# MCAN register map
Vendor: Texas Instruments
Registers are 32-bit, access per field, reset 0x0 unless marked. A register's access mark holds for its fields unless they carry their own. Offsets are as the file gives them; [hi:lo] are bit positions; {n}, {i} and the like mark numbered series; 'fields as' and 'values as' point back to an identical list.

## MCAN
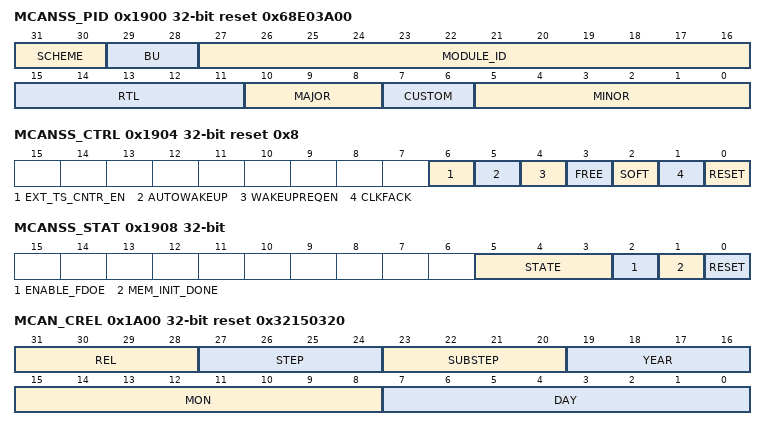
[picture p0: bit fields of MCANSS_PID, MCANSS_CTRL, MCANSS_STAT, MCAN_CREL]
0x1900 MCANSS_PID ro reset 0x68E03A00 — Revision Register The Revision Register contains the major and minor revisions for the module.
  [31:30] SCHEME — PID register scheme
  [29:28] BU — Business Unit: 0x2 = Processors
  [27:16] MODULE_ID
  [15:11] RTL — RTL revision
  [10:8] MAJOR — Major revision
  [7:6] CUSTOM
  [5:0] MINOR — Minor revision
0x1904 MCANSS_CTRL reset 0x8 — Control Register The Control Register contains general control bits for the MCAN module.
  [6] EXT_TS_CNTR_EN rw — External Timestamp Counter Enable
  [5] AUTOWAKEUP rw — Automatic Wakeup Enable
  [4] WAKEUPREQEN rw — Wakeup Request Enable
  [3] FREE rw — 0x0: Disregard debug suspend 0x1: Enable Debug Suspend
  [2] SOFT rw — If FREE = 0x1: 0x0: debug suspend doesn't wait for Idle 0x1: debug suspend waits for Idle
  [1] CLKFACK rw — Clock Fast Ack
  [0] RESET wo — Initiates a Soft Reset
0x1908 MCANSS_STAT ro (reset mask 0xFFFFFFFB) — Status Regsiter The Status register provide general status bits for the MCAN module.
  [5:3] STATE — 0x0: Active 0x1: In transition to Idle 0x2: Idle 0x3: In transition to Active
  [2] ENABLE_FDOE — Enable CAN FD configuration
  [1] MEM_INIT_DONE — 0x0: Memory Initialization is in progress 0x1: Memory Intialization Done
  [0] RESET — 0x0: Not in reset 0x1: Reset is in progress
0x190C MCANSS_ICS — Interrupt Clear Shadow Register Write to clear interrupt bits.
  [0] EXT_TS_CNTR_OVFL wo — External Timestamp Counter Overflow Interrupt status. Write '1' to clear bits.
0x1910 MCANSS_IRS access not given — Interrupt Raw Status Register Read raw interrupt status. Write '1' to set interrupt bits.
  [0] EXT_TS_CNTR_OVFL — External Timestamp Counter Overflow Interrupt status. (access RW1TS)
0x1914 MCANSS_IECS — Interrupt Enable Clear Shadow Register Write to clear interrupt enable bits.
  [0] EXT_TS_CNTR_OVFL wo — External Timestamp Counter Overflow Interrupt. Write '1' to clear bits.
0x1918 MCANSS_IE access not given — Interrupt Enable Register Read interrupt Enable.
  [0] EXT_TS_CNTR_OVFL — External Timestamp Counter Overflow Interrupt. (access RW1TS)
0x191C MCANSS_IES ro — Interrupt Enable Status Read Enabled Interrupts.
  [0] EXT_TS_CNTR_OVFL — External Timestamp Counter Overflow Interrupt.
0x1920 MCANSS_EOI — End Of Interrupt End of Interrupt Register.
  [7:0] EOI wo — Write with bit position of targetted interrupt (example: External TS is bit 0). Upon write, level interrupt will clear and if unserviced interrupt counter &gt; 1 will issue another pulse interrupt.
0x1924 MCANSS_EXT_TS_PRESCALER — External Timestamp PreScaler 0 External TImeStamp PreScaler.
  [23:0] PRESCALER rw — External Timestamp Prescaler reload value. External Timestamp count rate is Host clock (MCAN_ICLK) rate divided by this vlaue.
0x1928 MCANSS_EXT_TS_UNSERVICED_INTR_CNTR ro — External Timestamp PreScaler 0 Unserviced Interrupts Counter External TImeStamp Unserviced Interrupts Counter.
  [4:0] EXT_TS_INTR_CNTR — Number of unserviced rollover interupts. If &gt; 1 an EOI write will issue another pulse interrupt.
0x1980 MCANSS_ECC_EOI — ECC EOI End Of Interrupt for ECC interrupt.
  [8] ECC_EOI wo
0x1A00 MCAN_CREL ro reset 0x32150320 — Core Release Register Release dependent constant (version + date).
  [31:28] REL — Core Release One digit, BCD-coded.
  [27:24] STEP — Step of Core Release One digit, BCD-coded.
  [23:20] SUBSTEP — Sub-step of Core Release One digit, BCD-coded.
  [19:16] YEAR — Time Stamp Year One digit, BCD-coded.
  [15:8] MON — Time Stamp Month Two digits, BCD-coded.
  [7:0] DAY — Time Stamp Day Two digits, BCD-coded.
0x1A04 MCAN_ENDN ro reset 0x87654321 — Endian Register Constant 0x8765 4321.
  [31:0] ETV — Endianness Test Value The endianness test value is 0x8765 4321.
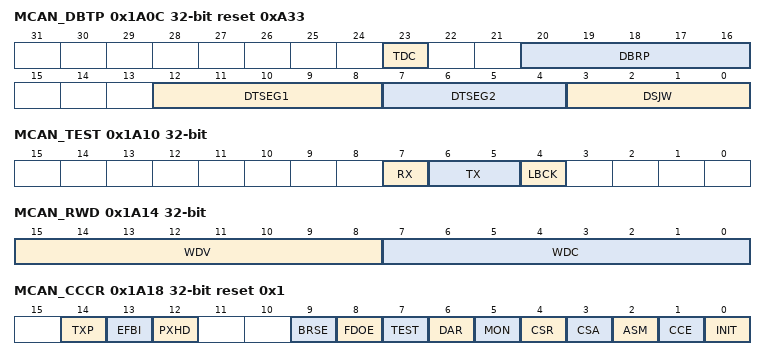
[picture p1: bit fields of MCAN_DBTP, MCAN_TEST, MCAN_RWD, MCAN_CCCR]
0x1A0C MCAN_DBTP reset 0xA33 — Data Bit Timing & Prescaler Register Configuration of data phase bit timing, transmitter delay compensation enable. This register is only writable if the The Therefore the length of the bit time is (programmed values) [
  [23] TDC rw — Transmitter Delay Compensation 0x0: Transmitter Delay Compensation disabled 0x1: Transmitter Delay Compensation enabled
  [20:16] DBRP rw — Data Baud Rate Prescaler The value by which the oscillator frequency is divided for generating the bit time quanta. The bit time is built up from a multiple of this quanta. Valid values for the Baud Rate Prescaler are 0 to 31 (0x00-0x1F). The actual interpretation by the hardware of this value is such that one more than the value programmed here is used.
  [12:8] DTSEG1 rw — Data time segment before sample point Valid values are 0 to 31 (0x00-0x1F). The actual interpretation by the hardware of this value is such that one more than the programmed value is used.
  [7:4] DTSEG2 rw — Data time segment after sample point Valid values are 0 to 15 (0x0-0xF). The actual interpretation by the hardware of this value is such that one more than the programmed value is used.
  [3:0] DSJW rw — Data (Re)Synchronization Jump Width Valid values are 0 to 15 (0x0-0xF). The actual interpretation by the hardware of this value is such that one more than the value programmed here is used.
0x1A10 MCAN_TEST — Test Register Test mode selection. Write access to the Test Register has to be enabled by setting the Loop Back Mode and software control of the mcan_tx pin are hardware test modes. Programming of the
  [7] RX ro — Receive Pin Monitors the actual value of the mcan_rx pin 0x0: The CAN bus is dominant (mcan_rx = '0') 0x1: The CAN bus is recessive (mcan_rx = '1')
  [6:5] TX rw — Control of Transmit Pin 0x0: Reset value, the mcan_tx pin controlled by the CAN Core, updated at the end of the CAN bit time 0x1: Sample Point can be monitored at the mcan_tx pin 0x2: Dominant ('0') level at the mcan_tx pin 0x3: Recessive ('1') at the mcan_tx pin
  [4] LBCK rw — Loop Back Mode 0x0: Reset value, Loop Back Mode is disabled 0x1: Loop Back Mode is enabled
0x1A14 MCAN_RWD — RAM Watchdog Monitors the READY output of the Message RAM. The RAM Watchdog monitors the READY output of the Message RAM. A Message RAM access starts the Message RAM Watchdog Counter with the value configured by the
  [15:8] WDV ro — Watchdog Value Actual Message RAM Watchdog Counter Value.
  [7:0] WDC rw — Watchdog Configuration Start value of the Message RAM Watchdog Counter. With the reset value of '00' the counter is disabled.
0x1A18 MCAN_CCCR reset 0x1 — CC Control Register Operation mode configuration. For details about setting and resetting of single bits, see
  [14] TXP rw — Transmit Pause If this bit is set, the MCAN module pauses for two CAN bit times before starting the next transmission after itself has successfully transmitted a frame 0x0: Transmit pause disabled 0x1: Transmit pause enabled
  [13] EFBI rw — Edge Filtering during Bus Integration 0x0: Edge filtering disabled 0x1: Two consecutive dominant t
  [12] PXHD rw — Protocol Exception Handling Disable 0x0: Protocol exception handling enabled 0x1: Protocol exception handling disabled
  [9] BRSE rw — Bit Rate Switch Enable 0x0: Bit rate switching for transmissions disabled 0x1: Bit rate switching for transmissions enabled
  [8] FDOE rw — FD Operation Enable 0x0: FD operation disabled 0x1: FD operation enabled
  [7] TEST rw — Test Mode Enable 0x0: Normal operation. The 0x1: Test Mode. Write access to the
  [6] DAR rw — Disable Automatic Retransmission 0x0: Automatic retransmission of messages not transmitted successfully enabled 0x1: Automatic retransmission disabled
  [5] MON rw — Bus Monitoring Mode The 0x0: Bus Monitoring Mode is disabled 0x1: Bus Monitoring Mode is enabled
  [4] CSR rw — Clock Stop Request 0x0: No clock stop is requested 0x1: Clock stop requested. When clock stop is requested, first the
  [3] CSA ro — Clock Stop Acknowledge 0x0: No clock stop acknowledged 0x1: The MCAN module may be set in power down by stopping MCAN_ICLK and MCAN_FCLK
  [2] ASM rw — Restricted Operation Mode The 0x0: Normal CAN operation 0x1: Restricted Operation Mode active
  [1] CCE rw — Configuration Change Enable 0x0: The Host CPU has no write access to the protected configuration registers 0x1: The Host CPU has write access to the protected configuration registers (while the
  [0] INIT rw — Initialization 0x0: Normal Operation 0x1: Initialization is started
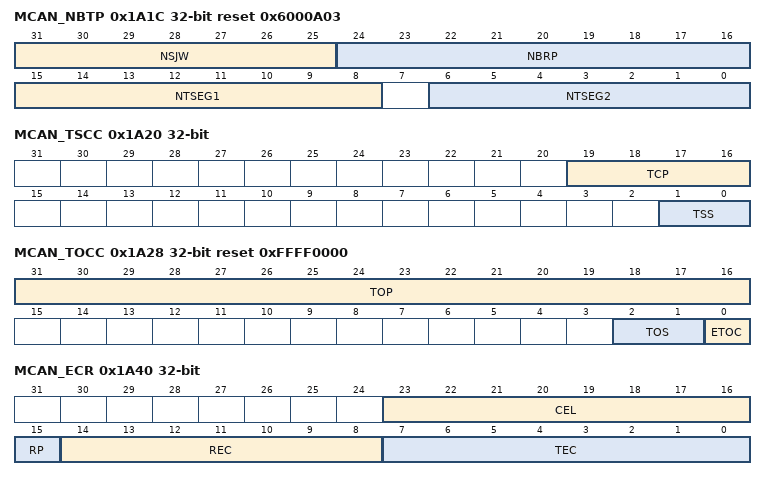
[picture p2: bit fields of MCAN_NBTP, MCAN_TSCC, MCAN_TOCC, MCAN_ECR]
0x1A1C MCAN_NBTP reset 0x6000A03 — Nominal Bit Timing & Prescaler Register Configuration of arbitration phase bit timing. This register is only writable if the Therefore the length of the bit time is (programmed values) [ The Information Processing Time (IPT) is zero, meaning the data for the next bit is available at the first clock edge after the sample point.
  [31:25] NSJW rw — Nominal (Re)Synchronization Jump Width Valid values are 0 to 127 (0x00-0x7F). The actual interpretation by the hardware of this value is such that one more than the value programmed here is used.
  [24:16] NBRP rw — Nominal Baud Rate Prescaler The value by which the oscillator frequency is divided for generating the bit time quanta. The bit time is built up from a multiple of this quanta. Valid values for the Baud Rate Prescaler are 0 to 511 (0x000-0x1FF). The actual interpretation by the hardware of this value is such that one more than the value programmed here is used.
  [15:8] NTSEG1 rw — Nominal Time segment before sample point Valid values are 1 to 255 (0x01-0xFF). The actual interpretation by the hardware of this value is such that one more than the programmed value is used.
  [6:0] NTSEG2 rw — Nominal Time segment after sample point Valid values are 0 to 127 (0x00-0x7F). The actual interpretation by the hardware of this value is such that one more than the programmed value is used.
0x1A20 MCAN_TSCC — Timestamp Counter Configuration Timestamp counter prescaler setting, selection of internal/external timestamp vector. For a description of the Timestamp Counter, see
  [19:16] TCP rw — Timestamp Counter Prescaler Configures the timestamp and timeout counters time unit in multiples of CAN bit times [1-16 (0x0-0xF)]. The actual interpretation by the hardware of this value is such that one more than the value programmed here is used.
  [1:0] TSS rw — Timestamp Select 0x0: Timestamp counter value always 0x0000 0x1: Timestamp counter value incremented according to the 0x2: External timestamp counter value used 0x3: Same as '00'
0x1A24 MCAN_TSCV access not given — Timestamp Counter Value Read/reset timestamp counter.
  [15:0] TSC — Timestamp Counter The internal/external Timestamp Counter value is captured on start of frame (both Rx and Tx). When the [1-16] depending on the configuration of the Write access resets the counter to zero. When the (access RWTC)
0x1A28 MCAN_TOCC reset 0xFFFF0000 — Timeout Counter Configuration Configuration of timeout period, selection of timeout counter operation mode. For a description of the Timeout Counter, see
  [31:16] TOP rw — Timeout Period Start value of the Timeout Counter (down-counter). Configures the Timeout Period.
  [2:1] TOS rw — Timeout Select When operating in Continuous mode, a write to the 0x0: Continuous operation 0x1: Timeout controlled by Tx Event FIFO 0x2: Timeout controlled by Rx FIFO 0 0x3: Timeout controlled by Rx FIFO 1
  [0] ETOC rw — Enable Timeout Counter 0x0: Timeout Counter disabled 0x1: Timeout Counter enabled
0x1A2C MCAN_TOCV access not given reset 0xFFFF — Timeout Counter Value Read/reset timeout counter.
  [15:0] TOC — Timeout Counter The Timeout Counter is decremented in multiples of CAN bit times [1-16] depending on the configuration of the (access RWTC)
0x1A40 MCAN_ECR ro — Error Counter Register State of Rx/Tx Error Counter, CAN Error Logging.
  [23:16] CEL — CAN Error Logging The counter is incremented each time when a CAN protocol error causes the Transmit Error Counter or the Receive Error Counter to be incremented. It is reset by read access to the
  [15] RP — Receive Error Passive 0x0: The Receive Error Counter is below the error passive level of 128 0x1: The Receive Error Counter has reached the error passive level of 128
  [14:8] REC — Receive Error Counter Actual state of the Receive Error Counter, values between 0 and 127.
  [7:0] TEC — Transmit Error Counter Actual state of the Transmit Error Counter, values between 0 and 255.
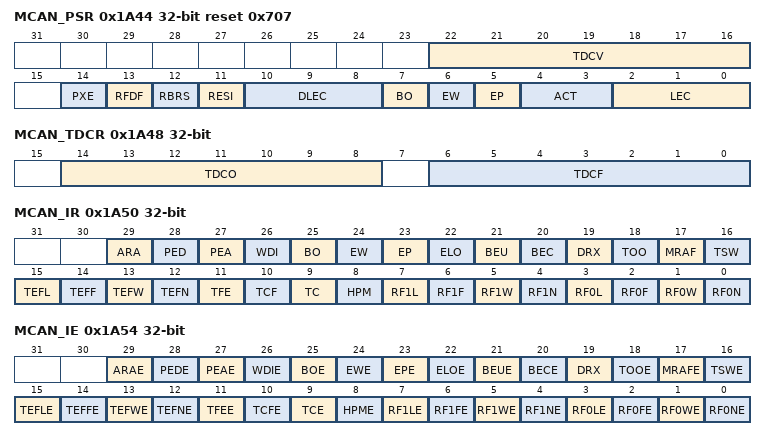
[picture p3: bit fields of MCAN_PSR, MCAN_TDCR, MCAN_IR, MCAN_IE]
0x1A44 MCAN_PSR ro reset 0x707 — Protocol Status Register CAN protocol controller status, transmitter delay compensation value.
  [22:16] TDCV — Transmitter Delay Compensation Value Position of the secondary sample point, defined by the sum of the measured delay from the mcan_tx to mcan_rx pins and the
  [14] PXE — Protocol Exception Event 0x0: No protocol exception event occurred since last read access 0x1: Protocol exception event occurred
  [13] RFDF — Received a CAN FD Message This bit is set independent of acceptance filtering. 0x0: Since this bit was reset by the Host CPU, no CAN FD message has been received 0x1: Message in CAN FD format with FDF flag set has been received
  [12] RBRS — BRS flag of last received CAN FD Message This bit is set together with the 0x0: Last received CAN FD message did not have its BRS flag set 0x1: Last received CAN FD message had its BRS flag set
  [11] RESI — ESI flag of last received CAN FD Message This bit is set together with the 0x0: Last received CAN FD message did not have its ESI flag set 0x1: Last received CAN FD message had its ESI flag set
  [10:8] DLEC — Data Phase Last Error Code Type of last error that occurred in the data phase of a CAN FD format frame with its BRS flag set. Coding is the same as for the
  [7] BO — Bus_Off Status 0x0: The MCAN module is not Bus_Off 0x1: The MCAN module is in Bus_Off state
  [6] EW — Warning Status 0x0: Both error counters are below the Error_Warning limit of 96 0x1: At least one of error counter has reached the Error_Warning limit of 96
  [5] EP — Error Passive 0x0: The MCAN module is in the Error_Active state. It normally takes part in bus communication and sends an active error flag when an error has been detected 0x1: The MCAN module is in the Error_Passive state
  [4:3] ACT — Activity Monitors the module's CAN communication state. 0x0: Synchronizing - node is synchronizing on CAN communication 0x1: Idle - node is neither receiver nor transmitter 0x2: Receiver - node is operating as receiver 0x3: Transmitter - node is operating as transmitter
  [2:0] LEC — Last Error Code The 0x0: No Error: No error occurred since the 0x1: Stuff Error: More than 5 equal bits in a sequence have occurred in a part of a received message where this is not allowed. 0x2: Form Error: A fixed format part of a received frame has the wrong format. 0x3: AckError: The message transmitted by the MCAN module was not acknowledged by another node. 0x4: Bit1Error: During the transmission of a message (with the exception of the arbitration field), the device wanted to send a recessive level (bit of logical value '1'), but the monitored bus value was dominant. 0x5: Bit0Error: During the transmission of a message (or acknowledge bit, or active error flag, or overload flag), the device wanted to send a dominant level (data or identifier bit logical value '0'), but the monitored bus value was recessive. During Bus_Off recovery this status is set each time a sequence of 11 recessive bits has been monitored. This enables the Host CPU to monitor the proceeding of the Bus_Off recovery sequence (indicating the bus is not stuck at dominant or continuously disturbed). 0x6: CRCError: The CRC check sum of a received message was incorrect. The CRC of an incom-ing message does not match with the CRC calculated from the received data. 0x7: NoChange: Any read access to the Protocol Status Register re-initializes the
0x1A48 MCAN_TDCR — Transmitter Delay Comensation Register Configuration of transmitter delay compensation offset and filter window length.
  [14:8] TDCO rw — Transmitter Delay Compensation Offset Offset value defining the distance between the measured delay from the mcan_rx and mcan_tx pins and the secondary sample point. Valid values are 0 to 127 mtq (0x00-0x7F).
  [6:0] TDCF rw — Transmitter Delay Compensation Filter Window Length Defines the minimum value for the SSP position, dominant edges on the mcan_rx pin that would result in an earlier SSP position are ignored for transmitter delay measure-ment. The feature is enabled when the
0x1A50 MCAN_IR access not given — Interrupt RegisterThe flags are set when one of the listed conditions is detected (edge-sensitive). The flags remain set until the Host CPU clears them. A flag is cleared by writing a '1' to the corresponding bit position. Writing a '0' has no effect. A hard reset will clear the register. The configuration of the
  [29] ARA — Access to Reserved Address 0x0: No access to reserved address occurred 0x1: Access to reserved address occurred (access RW1TC)
  [28] PED — Protocol Error in Data Phase 0x0: No protocol error in data phase 0x1: Protocol error in data phase detected ( (access RW1TC)
  [27] PEA — Protocol Error in Arbitration Phase 0x0: No protocol error in arbitration phase 0x1: Protocol error in arbitration phase detected ( (access RW1TC)
  [26] WDI — Watchdog Interrupt 0x0: No Message RAM Watchdog event occurred 0x1: Message RAM Watchdog event due to missing READY (access RW1TC)
  [25] BO — Bus_Off Status 0x0: Bus_Off status unchanged 0x1: Bus_Off status changed (access RW1TC)
  [24] EW — Warning Status 0x0: Error_Warning status unchanged 0x1: Error_Warning status changed (access RW1TC)
  [23] EP — Error Passive 0x0: Error_Passive status unchanged 0x1: Error_Passive status changed (access RW1TC)
  [22] ELO — Error Logging Overflow 0x0: CAN Error Logging Counter did not overflow 0x1: Overflow of CAN Error Logging Counter occurred (access RW1TC)
  [21] BEU — Bit Error Uncorrected Message RAM bit error detected, uncorrected. Controlled by input signal generated by parity / ECC logic attached to the Message RAM. An uncorrected Message RAM bit error sets the 0x0: No bit error detected when reading from Message RAM 0x1: Bit error detected, uncorrected (example: parity logic) (access RW1TC)
  [20] BEC — Bit Error Corrected Message RAM bit error detected and corrected. Controlled by input signal generated by parity / ECC logic attached to the Message RAM. 0x0: No bit error detected when reading from Message RAM 0x1: Bit error detected and corrected (example: ECC) (access RW1TC)
  [19] DRX — Message stored to Dedicated Rx Buffer The flag is set whenever a received message has been stored into a dedicated Rx Buffer. 0x0: No Rx Buffer updated 0x1: At least one received message stored into an Rx Buffer (access RW1TC)
  [18] TOO — Timeout Occurred 0x0: No timeout 0x1: Timeout reached (access RW1TC)
  [17] MRAF — Message RAM Access Failure The flag is set, when the Rx Handler: • has not completed acceptance filtering or storage of an accepted message until the arbitration field of the following message has been received. In this case acceptance filtering or message storage is aborted and the Rx Handler starts processing of the following message. • was not able to write a message to the Message RAM. In this case message storage is aborted. In both cases the FIFO put index is not updated respectively the New Data flag for a dedicated Rx Buffer is not set, a partly stored message is overwritten when the next message is stored to this location. The flag is also set when the Tx Handler was not able to read a message from the Message RAM in time. In this case message transmission is aborted. In case of a Tx Handler access failure the MCAN module is switched into Restricted Operation Mode (see 0x0: No Message RAM access failure occurred 0x1: Message RAM access failure occurred (access RW1TC)
  [16] TSW — Timestamp Wraparound 0x0: No timestamp counter wrap-around 0x1: Timestamp counter wrapped around (access RW1TC)
  [15] TEFL — Tx Event FIFO Element Lost 0x0: No Tx Event FIFO element lost 0x1: Tx Event FIFO element lost, also set after write attempt to Tx Event FIFO of size zero (access RW1TC)
  [14] TEFF — Tx Event FIFO Full 0x0: Tx Event FIFO not full 0x1: Tx Event FIFO full (access RW1TC)
  [13] TEFW — Tx Event FIFO Watermark Reached 0x0: Tx Event FIFO fill level below watermark 0x1: Tx Event FIFO fill level reached watermark (access RW1TC)
  [12] TEFN — Tx Event FIFO New Entry 0x0: Tx Event FIFO unchanged 0x1: Tx Handler wrote Tx Event FIFO element (access RW1TC)
  [11] TFE — Tx FIFO Empty 0x0: Tx FIFO non-empty 0x1: Tx FIFO empty (access RW1TC)
  [10] TCF — Transmission Cancellation Finished 0x0: No transmission cancellation finished 0x1: Transmission cancellation finished (access RW1TC)
  [9] TC — Transmission Completed 0x0: No transmission completed 0x1: Transmission completed (access RW1TC)
  [8] HPM — High Priority Message 0x0: No high priority message received 0x1: High priority message received (access RW1TC)
  [7] RF1L — Rx FIFO 1 Message Lost 0x0: No Rx FIFO 1 message lost 0x1: Rx FIFO 1 message lost, also set after write attempt to Rx FIFO 1 of size zero (access RW1TC)
  [6] RF1F — Rx FIFO 1 Full 0x0: Rx FIFO 1 not full 0x1: Rx FIFO 1 full (access RW1TC)
  [5] RF1W — Rx FIFO 1 Watermark Reached 0x0: Rx FIFO 1 fill level below watermark 0x1: Rx FIFO 1 fill level reached watermark (access RW1TC)
  [4] RF1N — Rx FIFO 1 New Message 0x0: No new message written to Rx FIFO 1 0x1: New message written to Rx FIFO 1 (access RW1TC)
  [3] RF0L — Rx FIFO 0 Message Lost 0x0: No Rx FIFO 0 message lost 0x1: Rx FIFO 0 message lost, also set after write attempt to Rx FIFO 0 of size zero (access RW1TC)
  [2] RF0F — Rx FIFO 0 Full 0x0: Rx FIFO 0 not full 0x1: Rx FIFO 0 full (access RW1TC)
  [1] RF0W — Rx FIFO 0 Watermark Reached 0x0: Rx FIFO 0 fill level below watermark 0x1: Rx FIFO 0 fill level reached watermark (access RW1TC)
  [0] RF0N — Rx FIFO 0 New Message 0x0: No new message written to Rx FIFO 0 0x1: New message written to Rx FIFO 0 (access RW1TC)
0x1A54 MCAN_IE — Interrupt EnableThe settings in the Interrupt Enable register determine which status changes in the Interrupt Register are signalled on an interrupt line.
  [29] ARAE rw — Access to Reserved Address Enable 0x0: Interrupt disabled 0x1: Interrupt enabled
  [28] PEDE rw — Protocol Error in Data Phase Enable 0x0: Interrupt disabled 0x1: Interrupt enabled
  [27] PEAE rw — Protocol Error in Arbitration Phase Enable 0x0: Interrupt disabled 0x1: Interrupt enabled
  [26] WDIE rw — Watchdog Interrupt Enable 0x0: Interrupt disabled 0x1: Interrupt enabled
  [25] BOE rw — Bus_Off Status Interrupt Enable 0x0: Interrupt disabled 0x1: Interrupt enabled
  [24] EWE rw — Warning Status Interrupt Enable 0x0: Interrupt disabled 0x1: Interrupt enabled
  [23] EPE rw — Error Passive Interrupt Enable 0x0: Interrupt disabled 0x1: Interrupt enabled
  [22] ELOE rw — Error Logging Overflow Interrupt Enable 0x0: Interrupt disabled 0x1: Interrupt enabled
  [21] BEUE rw — Bit Error Uncorrected Interrupt Enable 0x0: Interrupt disabled 0x1: Interrupt enabled
  [20] BECE rw — Bit Error Corrected Interrupt Enable 0x0: Interrupt disabled 0x1: Interrupt enabled
  [19] DRX rw — Message stored to Dedicated Rx Buffer Interrupt Enable
  [18] TOOE rw — Timeout Occurred Interrupt Enable 0x0: Interrupt disabled 0x1: Interrupt enabled
  [17] MRAFE rw — Message RAM Access Failure Interrupt Enable 0x0: Interrupt disabled 0x1: Interrupt enabled
  [16] TSWE rw — Timestamp Wraparound Interrupt Enable 0x0: Interrupt disabled 0x1: Interrupt enabled
  [15] TEFLE rw — Tx Event FIFO Event Lost Interrupt Enable 0x0: Interrupt disabled 0x1: Interrupt enabled
  [14] TEFFE rw — Tx Event FIFO Full Interrupt Enable 0x0: Interrupt disabled 0x1: Interrupt enabled
  [13] TEFWE rw — Tx Event FIFO Watermark Reached Interrupt Enable 0x0: Interrupt disabled 0x1: Interrupt enabled
  [12] TEFNE rw — Tx Event FIFO New Entry Interrupt Enable 0x0: Interrupt disabled 0x1: Interrupt enabled
  [11] TFEE rw — Tx FIFO Empty Interrupt Enable 0x0: Interrupt disabled 0x1: Interrupt enabled
  [10] TCFE rw — Transmission Cancellation Finished Interrupt Enable 0x0: Interrupt disabled 0x1: Interrupt enabled
  [9] TCE rw — Transmission Completed Interrupt Enable 0x0: Interrupt disabled 0x1: Interrupt enabled
  [8] HPME rw — High Priority Message Interrupt Enable 0x0: Interrupt disabled 0x1: Interrupt enabled
  [7] RF1LE rw — Rx FIFO 1 Message Lost Interrupt Enable 0x0: Interrupt disabled 0x1: Interrupt enabled
  [6] RF1FE rw — Rx FIFO 1 Full Interrupt Enable 0x0: Interrupt disabled 0x1: Interrupt enabled
  [5] RF1WE rw — Rx FIFO 1 Watermark Reached Interrupt Enable 0x0: Interrupt disabled 0x1: Interrupt enabled
  [4] RF1NE rw — Rx FIFO 1 New Message Interrupt Enable 0x0: Interrupt disabled 0x1: Interrupt enabled
  [3] RF0LE rw — Rx FIFO 0 Message Lost Interrupt Enable 0x0: Interrupt disabled 0x1: Interrupt enabled
  [2] RF0FE rw — Rx FIFO 0 Full Interrupt Enable 0x0: Interrupt disabled 0x1: Interrupt enabled
  [1] RF0WE rw — Rx FIFO 0 Watermark Reached Interrupt Enable 0x0: Interrupt disabled 0x1: Interrupt enabled
  [0] RF0NE rw — Rx FIFO 0 New Message Interrupt Enable 0x0: Interrupt disabled 0x1: Interrupt enabled
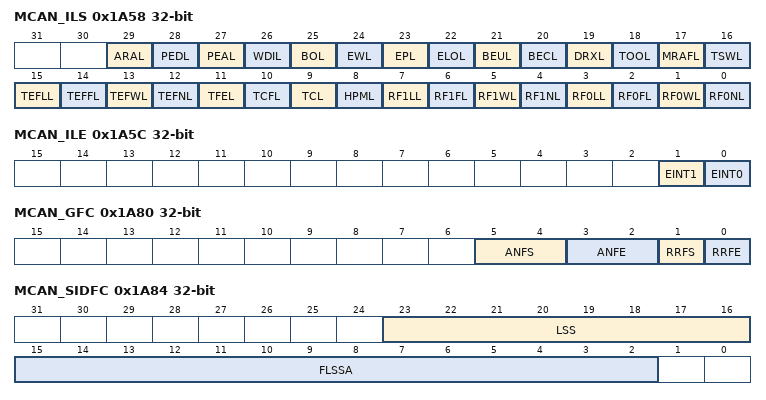
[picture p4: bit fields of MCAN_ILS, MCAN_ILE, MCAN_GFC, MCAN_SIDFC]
0x1A58 MCAN_ILS — Interrupt Line SelectThe Interrupt Line Select register assigns an interrupt generated by a specific interrupt flag from the Interrupt Register to one of the two module interrupt lines. For interrupt generation the respective interrupt line has to be enabled via the
  [29] ARAL rw — Access to Reserved Address Line 0x0: Interrupt assigned to interrupt line INT0 0x1: Interrupt assigned to interrupt line INT1
  [28] PEDL rw — Protocol Error in Data Phase Line 0x0: Interrupt assigned to interrupt line INT0 0x1: Interrupt assigned to interrupt line INT1
  [27] PEAL rw — Protocol Error in Arbitration Phase Line 0x0: Interrupt assigned to interrupt line INT0 0x1: Interrupt assigned to interrupt line INT1
  [26] WDIL rw — Watchdog Interrupt Line 0x0: Interrupt assigned to interrupt line INT0 0x1: Interrupt assigned to interrupt line INT1
  [25] BOL rw — Bus_Off Status Interrupt Line 0x0: Interrupt assigned to interrupt line INT0 0x1: Interrupt assigned to interrupt line INT1
  [24] EWL rw — Warning Status Interrupt Line 0x0: Interrupt assigned to interrupt line INT0 0x1: Interrupt assigned to interrupt line INT1
  [23] EPL rw — Error Passive Interrupt Line 0x0: Interrupt assigned to interrupt line INT0 0x1: Interrupt assigned to interrupt line INT1
  [22] ELOL rw — Error Logging Overflow Interrupt Line 0x0: Interrupt assigned to interrupt line INT0 0x1: Interrupt assigned to interrupt line INT1
  [21] BEUL rw — Bit Error Uncorrected Interrupt Line 0x0: Interrupt assigned to interrupt line INT0 0x1: Interrupt assigned to interrupt line INT1
  [20] BECL rw — Bit Error Corrected Interrupt Line 0x0: Interrupt assigned to interrupt line INT0 0x1: Interrupt assigned to interrupt line INT1
  [19] DRXL rw — Message stored to Dedicated Rx Buffer Interrupt Line 0x0: Interrupt assigned to interrupt line INT0 0x1: Interrupt assigned to interrupt line INT1
  [18] TOOL rw — Timeout Occurred Interrupt Line 0x0: Interrupt assigned to interrupt line INT0 0x1: Interrupt assigned to interrupt line INT1
  [17] MRAFL rw — Message RAM Access Failure Interrupt Line 0x0: Interrupt assigned to interrupt line INT0 0x1: Interrupt assigned to interrupt line INT1
  [16] TSWL rw — Timestamp Wraparound Interrupt Line 0x0: Interrupt assigned to interrupt line INT0 0x1: Interrupt assigned to interrupt line INT1
  [15] TEFLL rw — Tx Event FIFO Event Lost Interrupt Line 0x0: Interrupt assigned to interrupt line INT0 0x1: Interrupt assigned to interrupt line INT1
  [14] TEFFL rw — Tx Event FIFO Full Interrupt Line 0x0: Interrupt assigned to interrupt line INT0 0x1: Interrupt assigned to interrupt line INT1
  [13] TEFWL rw — Tx Event FIFO Watermark Reached Interrupt Line 0x0: Interrupt assigned to interrupt line INT0 0x1: Interrupt assigned to interrupt line INT1
  [12] TEFNL rw — Tx Event FIFO New Entry Interrupt Line 0x0: Interrupt assigned to interrupt line INT0 0x1: Interrupt assigned to interrupt line INT1
  [11] TFEL rw — Tx FIFO Empty Interrupt Line 0x0: Interrupt assigned to interrupt line INT0 0x1: Interrupt assigned to interrupt line INT1
  [10] TCFL rw — Transmission Cancellation Finished Interrupt Line 0x0: Interrupt assigned to interrupt line INT0 0x1: Interrupt assigned to interrupt line INT1
  [9] TCL rw — Transmission Completed Interrupt Line 0x0: Interrupt assigned to interrupt line INT0 0x1: Interrupt assigned to interrupt line INT1
  [8] HPML rw — High Priority Message Interrupt Line 0x0: Interrupt assigned to interrupt line INT0 0x1: Interrupt assigned to interrupt line INT1
  [7] RF1LL rw — Rx FIFO 1 Message Lost Interrupt Line 0x0: Interrupt assigned to interrupt line INT0 0x1: Interrupt assigned to interrupt line INT1
  [6] RF1FL rw — Rx FIFO 1 Full Interrupt Line 0x0: Interrupt assigned to interrupt line INT0 0x1: Interrupt assigned to interrupt line INT1
  [5] RF1WL rw — Rx FIFO 1 Watermark Reached Interrupt Line 0x0: Interrupt assigned to interrupt line INT0 0x1: Interrupt assigned to interrupt line INT1
  [4] RF1NL rw — Rx FIFO 1 New Message Interrupt Line 0x0: Interrupt assigned to interrupt line INT0 0x1: Interrupt assigned to interrupt line INT1
  [3] RF0LL rw — Rx FIFO 0 Message Lost Interrupt Line 0x0: Interrupt assigned to interrupt line INT0 0x1: Interrupt assigned to interrupt line INT1
  [2] RF0FL rw — Rx FIFO 0 Full Interrupt Line 0x0: Interrupt assigned to interrupt line INT0 0x1: Interrupt assigned to interrupt line INT1
  [1] RF0WL rw — Rx FIFO 0 Watermark Reached Interrupt Line 0x0: Interrupt assigned to interrupt line INT0 0x1: Interrupt assigned to interrupt line INT1
  [0] RF0NL rw — Rx FIFO 0 New Message Interrupt Line 0x0: Interrupt assigned to interrupt line INT0 0x1: Interrupt assigned to interrupt line INT1
0x1A5C MCAN_ILE — Interrupt Line Enable Enable/disable interrupt lines INT0/INT1. Each of the two interrupt lines to the Host CPU can be enabled / disabled separately by programming the
  [1] EINT1 rw — Enable Interrupt Line 1 0x0: Interrupt line INT1 disabled 0x1: Interrupt line INT1 enabled
  [0] EINT0 rw — Enable Interrupt Line 0 0x0: Interrupt line INT0 disabled 0x1: Interrupt line INT0 enabled
0x1A80 MCAN_GFC — Global Filter Configuration Handling of non-matching frames and remote frames. Global settings for Message ID filtering. The Global Filter Configuration controls the filter path for standard and extended messages (see
  [5:4] ANFS rw — Accept Non-matching Frames Standard Defines how received messages with 11-bit IDs that do not match any element of the filter list are treated. 0x0: Accept in Rx FIFO 0 0x1: Accept in Rx FIFO 1 0x2: Reject 0x3: Reject
  [3:2] ANFE rw — Accept Non-matching Frames Extended Defines how received messages with 29-bit IDs that do not match any element of the filter list are treated. 0x0: Accept in Rx FIFO 0 0x1: Accept in Rx FIFO 1 0x2: Reject 0x3: Reject
  [1] RRFS rw — Reject Remote Frames Standard 0x0: Filter remote frames with 11-bit standard IDs 0x1: Reject all remote frames with 11-bit standard IDs
  [0] RRFE rw — Reject Remote Frames Extended 0x0: Filter remote frames with 29-bit extended IDs 0x1: Reject all remote frames with 29-bit extended IDs
0x1A84 MCAN_SIDFC — Standard ID Filter Configuration Number of filter elements, pointer to start of filter list. Settings for 11-bit standard Message ID filtering. The Standard ID Filter Configuration controls the filter path for standard messages (see
  [23:16] LSS rw — List Size Standard 0x0: No standard Message ID filter 0x1-0x80 (1-128): Number of standard Message ID filter elements &gt; 0x80 (128): Values greater than 128 are interpreted as 128
  [15:2] FLSSA rw — Filter List Standard Start Address Start address of standard Message ID filter list (32-bit word address, see
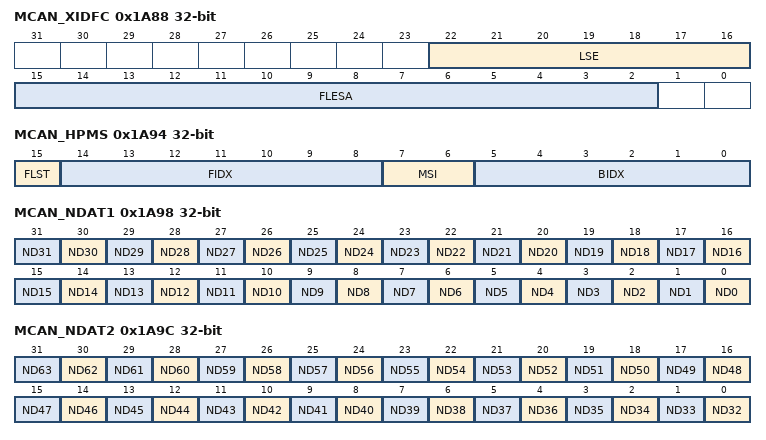
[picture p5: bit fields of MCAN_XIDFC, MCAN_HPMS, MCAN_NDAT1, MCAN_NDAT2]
0x1A88 MCAN_XIDFC — Extended ID Filter Configuration Number of filter elements, pointer to start of filter list. Settings for 29-bit extended Message ID filtering. The Extended ID Filter Configuration controls the filter path for standard messages (see
  [22:16] LSE rw — List Size Extended 0x0: No extended Message ID filter 0x1-0x40 (1-64): Number of extended Message ID filter elements &gt; 0x40 (64): Values greater than 64 are interpreted as 64
  [15:2] FLESA rw — Filter List Extended Start Address Start address of extended Message ID filter list (32-bit word address, see
0x1A90 MCAN_XIDAM reset 0x1FFFFFFF — Extended ID AND Mask 29-bit logical AND mask for J1939.
  [28:0] EIDM rw — Extended ID Mask For acceptance filtering of extended frames the Extended ID AND Mask is ANDed with the Message ID of a received frame. Intended for masking of 29-bit IDs in SAE J1939. With the reset value of all bits set to one the mask is not active.
0x1A94 MCAN_HPMS ro — High Priority Message Status Status monitoring of incoming high priority messages. This register is updated every time a Message ID filter element configured to generate a priority event matches. This can be used to monitor the status of incoming high priority messages and to enable fast access to these messages.
  [15] FLST — Filter List Indicates the filter list of the matching filter element. 0x0: Standard Filter List 0x1: Extended Filter List
  [14:8] FIDX — Filter Index Index of matching filter element. Range is 0 to
  [7:6] MSI — Message Storage Indicator 0x0: No FIFO selected 0x1: FIFO message lost 0x2: Message stored in FIFO 0 0x3: Message stored in FIFO 1
  [5:0] BIDX — Buffer Index Index of Rx FIFO element to which the message was stored. Only valid when the
0x1A98 MCAN_NDAT1 access not given — New Data 1 NewDat flags of dedicated Rx buffers 0-31. The register holds the New Data flags of Rx Buffers 0 to 31. The flags are set when the respective Rx Buffer has been updated from a received frame. The flags remain set until the Host CPU clears them. Aflag is cleared by writing a ’1’ to the corresponding bit position. Writing a ’0’ has no effect. Ahard reset will clear the register.
  [n] ND{n} (n=0..31) — New Data 0x0: Rx Buffer not updated 0x1: Rx Buffer updated from new message (access RW1TC)
0x1A9C MCAN_NDAT2 access not given — New Data 2 NewDat flags of dedicated Rx buffers 32-63. The register holds the New Data flags of Rx Buffers 32 to 63. The flags are set when the respective Rx Buffer has been updated from a received frame. The flags remain set until the Host CPU clears them. Aflag is cleared by writing a ’1’ to the corresponding bit position. Writing a ’0’ has no effect. Ahard reset will clear the register.
  [n-32] ND{n} (n=32..63) — New Data 0x0: Rx Buffer not updated 0x1: Rx Buffer updated from new message (access RW1TC)
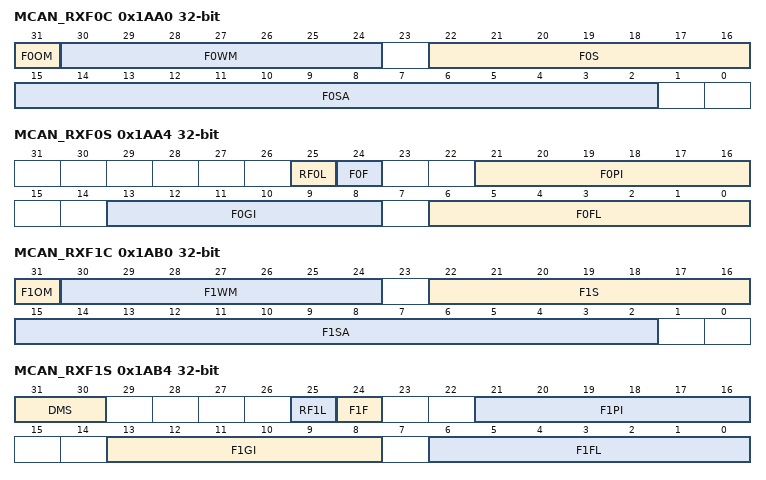
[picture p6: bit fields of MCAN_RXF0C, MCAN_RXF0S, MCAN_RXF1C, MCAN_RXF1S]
0x1AA0 MCAN_RXF0C — Rx FIFO 0 Configuration FIFO 0 operation mode, watermark, size and start address.
  [31] F0OM rw — FIFO 0 Operation Mode FIFO 0 can be operated in blocking or in overwrite mode (see 0x0: FIFO 0 blocking mode 0x1: FIFO 0 overwrite mode
  [30:24] F0WM rw — Rx FIFO 0 Watermark 0x0: Watermark interrupt disabled 0x1-0x40 (1-64): Level for Rx FIFO 0 watermark interrupt ( &gt; 0x40 (64): Watermark interrupt disabled
  [22:16] F0S rw — Rx FIFO 0 Size 0x0: No Rx FIFO 0 0x1-0x40 (1-64): Number of Rx FIFO 0 elements &gt; 0x40 (64): Values greater than 64 are interpreted as 64 The Rx FIFO 0 elements are indexed from 0 to
  [15:2] F0SA rw — Rx FIFO 0 Start Address Start address of Rx FIFO 0 in Message RAM (32-bit word address, see
0x1AA4 MCAN_RXF0S ro — Rx FIFO 0 Status FIFO 0 message lost/full indication, put index, get index and fill level.
  [25] RF0L — Rx FIFO 0 Message Lost This bit is a copy of interrupt flag 0x0: No Rx FIFO 0 message lost 0x1: Rx FIFO 0 message lost, also set after write attempt to Rx FIFO 0 of size zero
  [24] F0F — Rx FIFO 0 Full 0x0: Rx FIFO 0 not full 0x1: Rx FIFO 0 full
  [21:16] F0PI — Rx FIFO 0 Put Index Rx FIFO 0 write index pointer, range 0 to 63.
  [13:8] F0GI — Rx FIFO 0 Get Index Rx FIFO 0 read index pointer, range 0 to 63.
  [6:0] F0FL — Rx FIFO 0 Fill Level Number of elements stored in Rx FIFO 0, range 0 to 64.
0x1AA8 MCAN_RXF0A — Rx FIFO 0 Acknowledge FIFO 0 acknowledge last index of read buffers, updates get index and fill level.
  [5:0] F0AI rw — Rx FIFO 0 Acknowledge Index After the Host CPU has read a message or a sequence of messages from Rx FIFO 0 it has to write the buffer index of the last element read from Rx FIFO 0 to the
0x1AAC MCAN_RXBC — Rx Buffer Configuration Start address of Rx buffer section.
  [15:2] RBSA rw — Rx Buffer Start Address Configures the start address of the Rx Buffers section in the Message RAM Also used to reference debug messages A,B,C.
0x1AB0 MCAN_RXF1C — Rx FIFO 1 Configuration FIFO 1 operation mode, watermark, size and start address.
  [31] F1OM rw — FIFO 1 Operation Mode FIFO 1 can be operated in blocking or in overwrite mode (see 0x0: FIFO 1 blocking mode 0x1: FIFO 1 overwrite mode
  [30:24] F1WM rw — Rx FIFO 1 Watermark 0x0: Watermark interrupt disabled 0x1-0x40 (1-64): Level for Rx FIFO 1 watermark interrupt ( &gt; 0x40 (64): Watermark interrupt disabled
  [22:16] F1S rw — Rx FIFO 1 Size 0x0: No Rx FIFO 1 0x1-0x40 (1-64): Number of Rx FIFO 1 elements &gt; 0x40 (64): Values greater than 64 are interpreted as 64 The Rx FIFO 1 elements are indexed from 0 to
  [15:2] F1SA rw — Rx FIFO 1 Start Address Start address of Rx FIFO 1 in Message RAM (32-bit word address, see
0x1AB4 MCAN_RXF1S ro — Rx FIFO 1 Status FIFO 1 message lost/full indication, put index, get index and fill level.
  [31:30] DMS — Debug Message Status 0x0: Idle state, wait for reception of debug messages, DMA request is cleared 0x1: Debug message A received 0x2: Debug messages A, B received 0x3: Debug messages A, B, C received,
  [25] RF1L — Rx FIFO 1 Message Lost This bit is a copy of interrupt flag 0x0: No Rx FIFO 1 message lost 0x1: Rx FIFO 1 message lost, also set after write attempt to Rx FIFO 1 of size zero
  [24] F1F — Rx FIFO 1 Full 0x0: Rx FIFO 1 not full 0x1: Rx FIFO 1 full
  [21:16] F1PI — Rx FIFO 1 Put Index Rx FIFO 1 write index pointer, range 0 to 63.
  [13:8] F1GI — Rx FIFO 1 Get Index Rx FIFO 1 read index pointer, range 0 to 63.
  [6:0] F1FL — Rx FIFO 1 Fill Level Number of elements stored in Rx FIFO 1, range 0 to 64.
0x1AB8 MCAN_RXF1A — Rx FIFO 1 Acknowledge FIFO 1 acknowledge last index of read buffers, updates get index and fill level.
  [5:0] F1AI rw — Rx FIFO 1 Acknowledge Index After the Host CPU has read a message or a sequence of messages from Rx FIFO 1 it has to write the buffer index of the last element read from Rx FIFO 1 to the
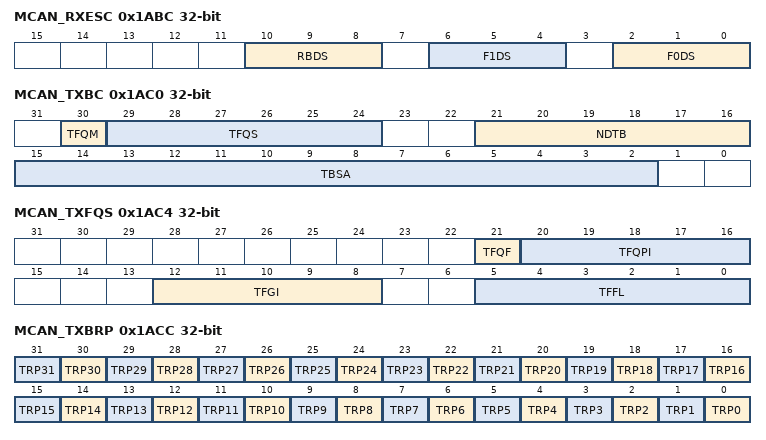
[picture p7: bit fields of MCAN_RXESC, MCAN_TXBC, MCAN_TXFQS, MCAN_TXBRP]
0x1ABC MCAN_RXESC — Rx Buffer / FIFO Element Size Configuration Configure data field size for storage of accepted frames.
  [10:8] RBDS rw — Rx Buffer Data Field Size 0x0: 8 byte data field 0x1: 12 byte data field 0x2: 16 byte data field 0x3: 20 byte data field 0x4: 24 byte data field 0x5: 32 byte data field 0x6: 48 byte data field 0x7: 64 byte data field
  [6:4] F1DS rw — Rx FIFO 1 Data Field Size 0x0: 8 byte data field 0x1: 12 byte data field 0x2: 16 byte data field 0x3: 20 byte data field 0x4: 24 byte data field 0x5: 32 byte data field 0x6: 48 byte data field 0x7: 64 byte data field
  [2:0] F0DS rw — Rx FIFO 0 Data Field Size 0x0: 8 byte data field 0x1: 12 byte data field 0x2: 16 byte data field 0x3: 20 byte data field 0x4: 24 byte data field 0x5: 32 byte data field 0x6: 48 byte data field 0x7: 64 byte data field
0x1AC0 MCAN_TXBC — Tx Buffer Configuration Configure Tx FIFO/Queue mode, Tx FIFO/Queue size, number of dedicated Tx buffers, Tx buffer start address.
  [30] TFQM rw — Tx FIFO/Queue Mode 0x0: Tx FIFO operation 0x1: Tx Queue operation
  [29:24] TFQS rw — Transmit FIFO/Queue Size 0x0: No Tx FIFO/Queue 0x1-0x20 (1-32): Number of Tx Buffers used for Tx FIFO/Queue &gt; 0x20 (32): Values greater than 32 are interpreted as 32
  [21:16] NDTB rw — Number of Dedicated Transmit Buffers 0x0: No Dedicated Tx Buffers 0x1-0x20 (1-32): Number of Dedicated Tx Buffers &gt; 0x20 (32): Values greater than 32 are interpreted as 32
  [15:2] TBSA rw — Tx Buffers Start Address Start address of Tx Buffers section in Message RAM (32-bit word address, see
0x1AC4 MCAN_TXFQS ro — Tx FIFO/Queue Status Tx FIFO/Queue full indication and put index, Tx FIFO get index and fill level. The Tx FIFO/Queue status is related to the pending Tx requests listed in the
  [21] TFQF — Tx FIFO/Queue Full 0x0: Tx FIFO/Queue not full 0x1: Tx FIFO/Queue full
  [20:16] TFQPI — Tx FIFO/Queue Put Index Tx FIFO/Queue write index pointer, range 0 to 31.
  [12:8] TFGI — Tx FIFO Get Index Tx FIFO read index pointer, range 0 to 31. Read as zero when Tx Queue operation is configured (
  [5:0] TFFL — Tx FIFO Free Level Number of consecutive free Tx FIFO elements starting from the
0x1AC8 MCAN_TXESC — Tx Buffer Element Size Configuration Configure data field size for frame transmission. Configures the number of data bytes belonging to a Tx Buffer element. Data field sizes > 8 bytes are intended for CAN FD operation only.
  [2:0] TBDS rw — Tx Buffer Data Field Size 0x0: 8 byte data field 0x1: 12 byte data field 0x2: 16 byte data field 0x3: 20 byte data field 0x4: 24 byte data field 0x5: 32 byte data field 0x6: 48 byte data field 0x7: 64 byte data field
0x1ACC MCAN_TXBRP ro — Tx Buffer Request Pending Tx buffers with pending transmission request. Each Tx Buffer has its own Transmission Request Pending bit. The bits are set via the The A cancellation request resets the corresponding transmission request pending bit of register the After a cancellation has been requested, a finished cancellation is signalled via the • after successful transmission together with the corresponding • when the transmission has not yet been started at the point of cancellation • when the transmission has been aborted due to lost arbitration • when an error occurred during frame transmission In DAR mode all transmissions are automatically cancelled if they are not successful. The corresponding
  [n] TRP{n} (n=0..31) — Transmission Request Pending 0x0: No transmission request pending 0x1: Transmission request pending
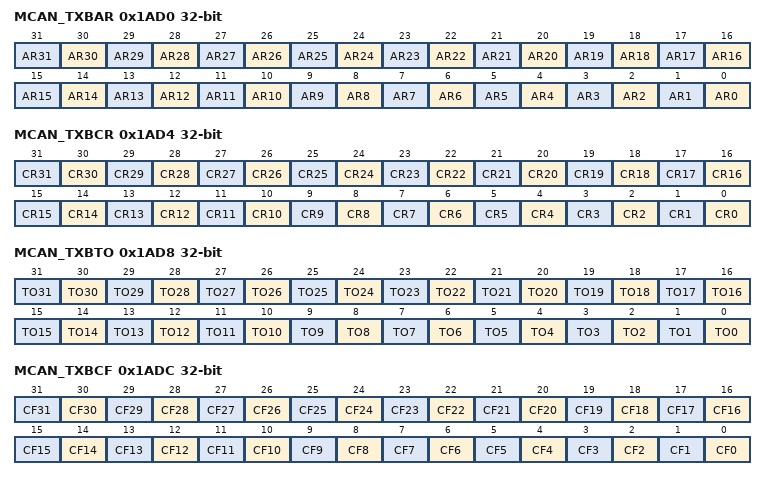
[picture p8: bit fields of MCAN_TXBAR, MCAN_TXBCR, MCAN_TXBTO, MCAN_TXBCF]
0x1AD0 MCAN_TXBAR access not given — Tx Buffer Add Request Add transmission requests. Each Tx Buffer has its own Add Request bit. Writing a ‘1’ will set the corresponding Add Request bit; writing a ‘0’ has no impact. This enables the Host CPU to set transmission requests for multiple Tx Buffers with one write to the
  [n] AR{n} (n=0..31) — Add Request 0x0: No transmission request added 0x1: Transmission requested added (access RW1TC)
0x1AD4 MCAN_TXBCR access not given — Tx Buffer Cancellation Request Request cancellation of pending transmissions. Each Tx Buffer has its own Cancellation Request bit. Writing a ‘1’ will set the corresponding Cancellation Request bit; writing a ‘0’ has no impact. This enables the Host CPU to set cancellation requests for multiple Tx Buffers with one write to the
  [n] CR{n} (n=0..31) — Cancellation Request 0x0: No cancellation pending 0x1: Cancellation pending (access RW1TC)
0x1AD8 MCAN_TXBTO ro — Tx Buffer Transmission Occurred Signals successful transmissions, set when corresponding flag is cleared. Each Tx Buffer has its own Transmission Occurred bit. The bits are set when the corresponding
  [n] TO{n} (n=0..31) — Transmission Occurred 0x0: No transmission occurred 0x1: Transmission occurred
0x1ADC MCAN_TXBCF ro — Tx Buffer Cancellation Finished Signals successful transmit cancellation, set when corresponding TXBRP flag is cleared after cancellation request. Each Tx Buffer has its own Cancellation Finished bit. The bits are set when the corresponding
  [n] CF{n} (n=0..31) — Cancellation Finished 0x0: No transmit buffer cancellation 0x1: Transmit buffer cancellation finished
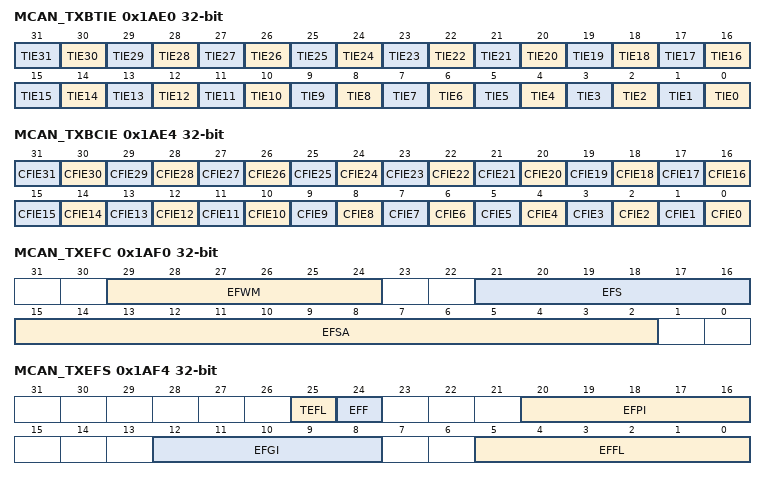
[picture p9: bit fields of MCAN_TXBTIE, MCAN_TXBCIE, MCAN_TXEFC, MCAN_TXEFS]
0x1AE0 MCAN_TXBTIE rw — Tx Buffer Transmission Interrupt Enable Enable transmit interrupts for selected Tx buffers.
  [n] TIE{n} (n=0..31) — Transmission Interrupt Enable 0x0: Transmission interrupt disabled 0x1: Transmission interrupt enable
0x1AE4 MCAN_TXBCIE rw — Tx Buffer Cancellation Finished Interrupt Enable Enable cancellation finished interrupts for selected Tx buffers.
  [n] CFIE{n} (n=0..31) — Cancellation Finished Interrupt Enable 0x0: Cancellation finished interrupt disabled 0x1: Cancellation finished interrupt enabled
0x1AF0 MCAN_TXEFC — Tx Event FIFO Configuration Tx event FIFO watermark, size and start address.
  [29:24] EFWM rw — Event FIFO Watermark 0x0: Watermark interrupt disabled 0x1-0x20 (1-32): Level for Tx Event FIFO watermark interrupt ( &gt; 0x20 (32): Watermark interrupt disabled
  [21:16] EFS rw — Event FIFO Size 0x0: Tx Event FIFO disabled 0x1-0x20 (1-32): Number of Tx Event FIFO elements &gt; 0x20 (32): Values greater than 32 are interpreted as 32 The Tx Event FIFO elements are indexed from 0 to
  [15:2] EFSA rw — Event FIFO Start Address Start address of Tx Event FIFO in Message RAM (32-bit word address, see
0x1AF4 MCAN_TXEFS ro — Tx Event FIFO Status Tx event FIFO element lost/full indication, put index, get index, and fill level.
  [25] TEFL — This bit is a copy of interrupt flag 0x0: No Tx Event FIFO element lost 0x1: Tx Event FIFO element lost, also set after write attempt to Tx Event FIFO of size zero.
  [24] EFF — Event FIFO Full 0x0: Tx Event FIFO not full 0x1: Tx Event FIFO full
  [20:16] EFPI — Event FIFO Put Index Tx Event FIFO write index pointer, range 0 to 31.
  [12:8] EFGI — Event FIFO Get Index Tx Event FIFO read index pointer, range 0 to 31.
  [5:0] EFFL — Event FIFO Fill Level Number of elements stored in Tx Event FIFO, range 0 to 32.
0x1AF8 MCAN_TXEFA — Tx Event FIFO Acknowledge Tx event FIFO acknowledge last index of read elements, updates get index and fill level.
  [4:0] EFAI rw — After the Host CPU has read an element or a sequence of elements from the Tx Event FIFO it has to write the index of the last element read from Tx Event FIFO to the
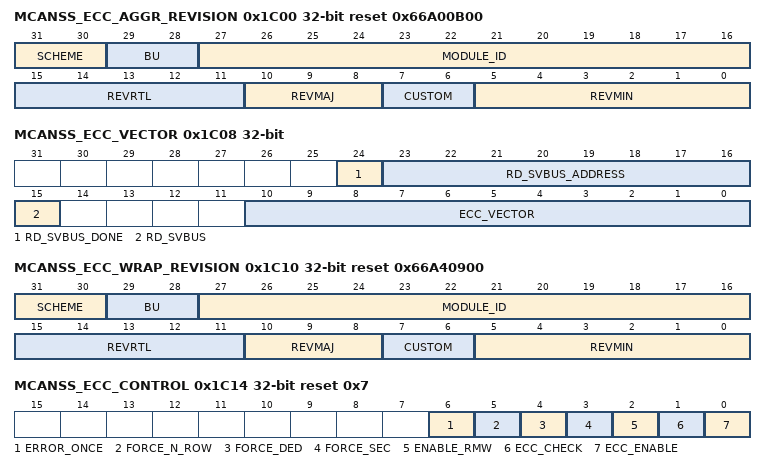
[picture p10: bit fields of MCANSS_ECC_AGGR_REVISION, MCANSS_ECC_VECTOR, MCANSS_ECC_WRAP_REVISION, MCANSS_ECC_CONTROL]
0x1C00 MCANSS_ECC_AGGR_REVISION ro reset 0x66A00B00 — Aggregator Revision Register Revision parameters.
  [31:30] SCHEME
  [29:28] BU — Business Unit
  [27:16] MODULE_ID
  [15:11] REVRTL — RTL version
  [10:8] REVMAJ — Major version
  [7:6] CUSTOM — Custom version
  [5:0] REVMIN — Minor version
0x1C08 MCANSS_ECC_VECTOR — ECC Vector Register ECC Vector Register.
  [24] RD_SVBUS_DONE ro — Status to indicate if read is complete
  [23:16] RD_SVBUS_ADDRESS rw — Read address
  [15] RD_SVBUS rw — Write '1' to trigger a read
  [10:0] ECC_VECTOR rw — Value written to select the corresponding ECC RAM for control or status
0x1C0C MCANSS_ECC_MISC_STATUS ro reset 0x1 — Misc Status Misc Status.
  [10:0] NUM_RAMS — Indicates the number of RAMS serviced by the ECC aggregator
0x1C10 MCANSS_ECC_WRAP_REVISION ro reset 0x66A40900 — ECC Wrapper Revision Register Revision parameters.
  fields as MCANSS_ECC_AGGR_REVISION
0x1C14 MCANSS_ECC_CONTROL reset 0x7 — ECC Control ECC Control Register.
  [6] ERROR_ONCE rw — Force Error only once
  [5] FORCE_N_ROW rw — Force Error on any RAM read
  [4] FORCE_DED rw — Force Double Bit Error
  [3] FORCE_SEC rw — Force Single Bit Error
  [2] ENABLE_RMW rw
  [1] ECC_CHECK rw — Enable ECC check
  [0] ECC_ENABLE rw — Enable ECC
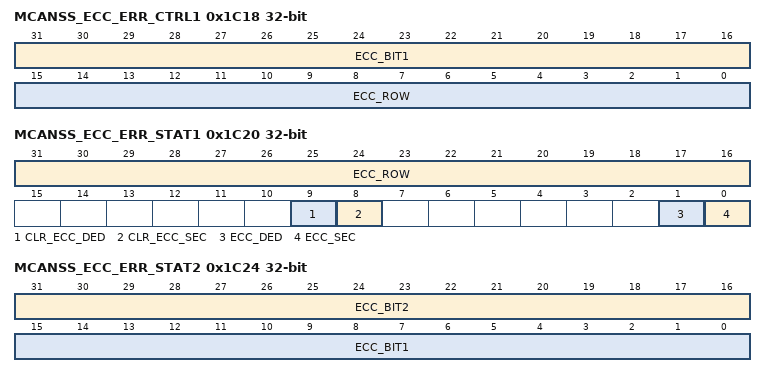
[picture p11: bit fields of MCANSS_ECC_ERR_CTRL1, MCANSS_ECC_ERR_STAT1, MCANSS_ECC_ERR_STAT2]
0x1C18 MCANSS_ECC_ERR_CTRL1 rw — ECC Error Control1 Register ECC Error Control1 Register.
  [31:16] ECC_BIT1 — Data bit that needs to be flipped when FORCE_SEC is set
  [15:0] ECC_ROW — Row address where single or double-bit error needs to be applied. This is ignored if FORCE_N_ROW is set.
0x1C1C MCANSS_ECC_ERR_CTRL2 — ECC Error Control2 Register ECC Error Control2 Register.
  [15:0] ECC_BIT2 rw — Data bit that needs to be flipped if double bit error needs to be forced
0x1C20 MCANSS_ECC_ERR_STAT1 access not given — ECC Error Status1 Register ECC Error Status1 Register.
  [31:16] ECC_ROW ro — Row address where the single or double-bit error has occurred
  [9] CLR_ECC_DED — Clear Double Bit Error Status (access RW1TC)
  [8] CLR_ECC_SEC — Clear Single Bit Error Status (access RW1TC)
  [1] ECC_DED — Level Double Bit Error Status (access RW1TS)
  [0] ECC_SEC — Level Single Bit Error Status (access RW1TS)
0x1C24 MCANSS_ECC_ERR_STAT2 ro — ECC Error Status2 Register ECC Error Status2 Register.
  [31:16] ECC_BIT2 — Data bit that corresponds to the double-bit error
  [15:0] ECC_BIT1 — Data bit that corresponds to the single-bit error
0x1C3C MCANSS_ECC_SEC_EOI_REG — EOI Register EOI Register.
  [0] EOI_WR rw — EOI Register
0x1C40 MCANSS_ECC_SEC_STATUS_REG0 access not given — Interrupt Status Register 0 Interrupt Status Register 0.
  [0] MSGMEM_PEND — Interrupt Pending Status for MSGMEM_PEND (access RW1TS)
0x1C80 MCANSS_ECC_SEC_ENABLE_SET_REG0 access not given — Interrupt Enable Set Register 0 Interrupt Enable Set Register 0.
  [0] MSGMEM_ENABLE_SET — Interrupt Enable Set Register for MSGMEM_PEND (access RW1TS)
0x1CC0 MCANSS_ECC_SEC_ENABLE_CLR_REG0 access not given — Interrupt Enable Clear Register 0 Interrupt Enable Clear Register 0.
  [0] MSGMEM_ENABLE_CLR — Interrupt Enable Clear Register for MSGMEM_PEND (access RW1TC)
0x1D3C MCANSS_ECC_DED_EOI_REG — EOI Register EOI Register.
  [0] EOI_WR rw — EOI Register
0x1D40 MCANSS_ECC_DED_STATUS_REG0 access not given — Interrupt Status Register 0 Interrupt Status Register 0.
  fields as MCANSS_ECC_SEC_STATUS_REG0
0x1D80 MCANSS_ECC_DED_ENABLE_SET_REG0 access not given — Interrupt Enable Set Register 0 Interrupt Enable Set Register 0.
  fields as MCANSS_ECC_SEC_ENABLE_SET_REG0
0x1DC0 MCANSS_ECC_DED_ENABLE_CLR_REG0 access not given — Interrupt Enable Clear Register 0 Interrupt Enable Clear Register 0.
  fields as MCANSS_ECC_SEC_ENABLE_CLR_REG0
